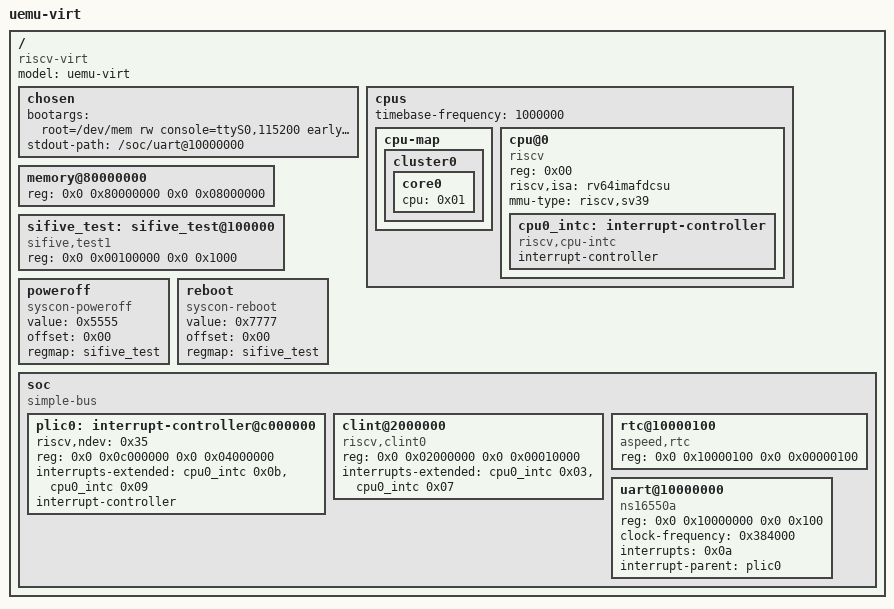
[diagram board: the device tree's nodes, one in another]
/*
 * Copyright 2025 Nuo Shen, Nanjing University
 *
 * Licensed under the Apache License, Version 2.0 (the "License");
 * you may not use this file except in compliance with the License.
 * You may obtain a copy of the License at
 *
 *     http://www.apache.org/licenses/LICENSE-2.0
 *
 * Unless required by applicable law or agreed to in writing, software
 * distributed under the License is distributed on an "AS IS" BASIS,
 * WITHOUT WARRANTIES OR CONDITIONS OF ANY KIND, either express or implied.
 * See the License for the specific language governing permissions and
 * limitations under the License.
 */

/dts-v1/;

/ {
    #address-cells = <0x02>;
    #size-cells = <0x02>;
    compatible = "riscv-virt";
    model = "uemu-virt";

    chosen {
        bootargs = "root=/dev/mem rw console=ttyS0,115200 earlycon=sbi";
        stdout-path = "/soc/uart@10000000";
    };

    cpus {
        #address-cells = <0x01>;
        #size-cells = <0x00>;
        timebase-frequency = <1000000>;

        cpu-map {
            cluster0 {
                core0 {
                    cpu = <0x01>;
                };
            };
        };

        cpu@0 {
            phandle = <0x01>;
            device_type = "cpu";
            reg = <0x00>;
            status = "okay";
            compatible = "riscv";
            riscv,isa = "rv64imafdcsu";
            mmu-type = "riscv,sv39";

            cpu0_intc: interrupt-controller {
                #interrupt-cells = <0x01>;
                interrupt-controller;
                compatible = "riscv,cpu-intc";
                phandle = <0x02>;
            };
        };
    };

    memory@80000000 {
        device_type = "memory";
        /* 0x8000000 = 128MB to match [0x80000000,0x87ffffff] */
        reg = <0x0 0x80000000 0x0 0x08000000>;
    };

    sifive_test: sifive_test@100000 {
        phandle = <0x04>;
        reg = <0x0 0x00100000 0x0 0x1000>;
        compatible = "sifive,test1\0sifive,test0\0syscon";
    };

    poweroff {
        value = <0x5555>;
        offset = <0x00>;
        regmap = <&sifive_test>;
        compatible = "syscon-poweroff";
    };

    reboot {
        value = <0x7777>;
        offset = <0x00>;
        regmap = <&sifive_test>;
        compatible = "syscon-reboot";
    };

    soc {
        #address-cells = <0x02>;
        #size-cells = <0x02>;
        compatible = "simple-bus";
        ranges;

        plic0: interrupt-controller@c000000 {
            phandle = <0x03>;
            riscv,ndev = <0x35>;
            /* base 0x0c000000, size 0x0400_000 */
            reg = <0x0 0x0c000000 0x0 0x04000000>;
            interrupts-extended = <&cpu0_intc 0x0b &cpu0_intc 0x09>;
            interrupt-controller;
            #interrupt-cells = <0x01>;
            #address-cells = <0x00>;
        };

        clint@2000000 {
            /* CLINT at 0x0200_0000, size 0x10000 */
            reg = <0x0 0x02000000 0x0 0x00010000>;
            interrupts-extended = <&cpu0_intc 0x03 &cpu0_intc 0x07>;
            compatible = "riscv,clint0";
        };

        rtc@10000100 {
            compatible = "aspeed,rtc";
            reg = <0x0 0x10000100 0x0 0x00000100>;
        };

        uart@10000000 {
            compatible = "ns16550a";
            reg = <0x0 0x10000000 0x0 0x100>;
            clock-frequency = <0x384000>;
            /* UART_IRQ = 10 */
            interrupts = <0x0a>;
            interrupt-parent = <&plic0>;
        };
    };
};
